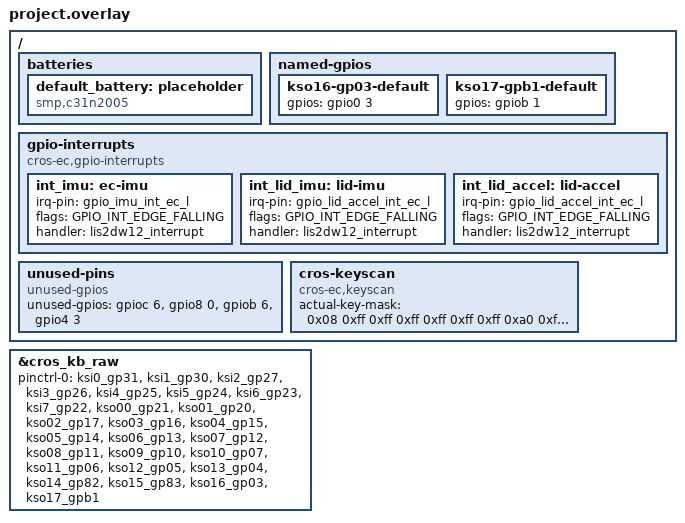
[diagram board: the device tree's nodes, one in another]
/* Copyright 2025 The ChromiumOS Authors
 * Use of this source code is governed by a BSD-style license that can be
 * found in the LICENSE file.
 */

#include <cros/cbi_flash.dtsi>
#include "../npcx_generated.dtsi"
#include "../interrupts.dtsi"
#include "../npcx_common.dtsi"
#include "../npcx_default_gpio_pinctrl.dtsi"
#include "../npcx_keyboard.dtsi"
#include "../npcx_overlay.dtsi"
#include "../npcx_usbc.dtsi"
#include "../power_signal.dtsi"
#include "../usba.dtsi"
#include "led_pins.dtsi"
#include "led_policy.dtsi"
#include "motionsense.dtsi"

/ {
	batteries {
		default_battery: placeholder {
			compatible = "smp,c31n2005", "battery-smart";
		};
	};

	named-gpios {
		/delete-node/ en_usb_c0_dev_mode;
		/delete-node/ usb_c0_dp_hpd;
		/delete-node/ ec_kso_02_inv;
		kso16-gp03-default {
			gpios = <&gpio0 3 (GPIO_OPEN_DRAIN | GPIO_PULL_UP)>;
		};
		kso17-gpb1-default {
			gpios = <&gpiob 1 (GPIO_OPEN_DRAIN | GPIO_PULL_UP)>;
		};
	};

	gpio-interrupts {
		compatible = "cros-ec,gpio-interrupts";

		/delete-node/ int_imu;

		int_imu: ec-imu {
			irq-pin = <&gpio_imu_int_ec_l>;
			flags = <GPIO_INT_EDGE_FALLING>;
			handler = "lis2dw12_interrupt";
		};
		int_lid_imu: lid-imu {
			irq-pin = <&gpio_lid_accel_int_ec_l>;
			flags = <GPIO_INT_EDGE_FALLING>;
			handler = "lis2dw12_interrupt";
		};
		int_lid_accel: lid-accel {
			irq-pin = <&gpio_lid_accel_int_ec_l>;
			flags = <GPIO_INT_EDGE_FALLING>;
			handler = "lis2dw12_interrupt";
		};
	};

	unused-pins {
		compatible = "unused-gpios";
		unused-gpios =
		<&gpioc 6 0>,
		<&gpio8 0 0>,
		<&gpiob 6 0>,
		<&gpio4 3 0>;
	};

	cros-keyscan {
		compatible = "cros-ec,keyscan";

		actual-key-mask = <
			0x08  /* C0 */
			0xff  /* C1 */
			0xff  /* C2 */
			0xff  /* C3 */
			0xff  /* C4 */
			0xff  /* C5 */
			0xff  /* C6 */
			0xa0  /* C7 */
			0xff  /* C8 */
			0xff  /* C9 */
			0x01  /* C10 */
			0xff  /* C11 */
			0xff  /* C12 */
			0x40  /* C13 */
			0x0a  /* C14 */
			0x40  /* C15 */
			0x01  /* C16 */
			0xc4  /* C17 */
		>;
	};
};

&cros_kb_raw {
	pinctrl-0 = <
		&ksi0_gp31
		&ksi1_gp30
		&ksi2_gp27
		&ksi3_gp26
		&ksi4_gp25
		&ksi5_gp24
		&ksi6_gp23
		&ksi7_gp22
		&kso00_gp21
		&kso01_gp20
		&kso02_gp17
		&kso03_gp16
		&kso04_gp15
		&kso05_gp14
		&kso06_gp13
		&kso07_gp12
		&kso08_gp11
		&kso09_gp10
		&kso10_gp07
		&kso11_gp06
		&kso12_gp05
		&kso13_gp04
		&kso14_gp82
		&kso15_gp83
		&kso16_gp03
		&kso17_gpb1
	>;
};
